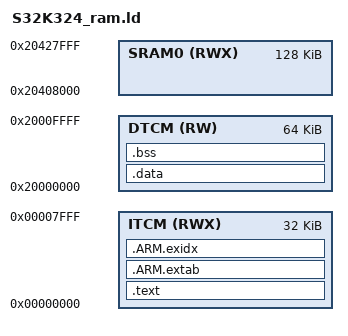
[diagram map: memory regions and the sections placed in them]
/*****************************************************************************
 *
 * Copyright 2020-2022 NXP
 * All Rights Reserved
 *
 *****************************************************************************
 *
 * THIS SOFTWARE IS PROVIDED BY NXP "AS IS" AND ANY EXPRESSED OR
 * IMPLIED WARRANTIES, INCLUDING, BUT NOT LIMITED TO, THE IMPLIED WARRANTIES
 * OF MERCHANTABILITY AND FITNESS FOR A PARTICULAR PURPOSE ARE DISCLAIMED.
 * IN NO EVENT SHALL NXP OR ITS CONTRIBUTORS BE LIABLE FOR ANY DIRECT,
 * INDIRECT, INCIDENTAL, SPECIAL, EXEMPLARY, OR CONSEQUENTIAL DAMAGES
 * (INCLUDING, BUT NOT LIMITED TO, PROCUREMENT OF SUBSTITUTE GOODS OR
 * SERVICES; LOSS OF USE, DATA, OR PROFITS; OR BUSINESS INTERRUPTION)
 * HOWEVER CAUSED AND ON ANY THEORY OF LIABILITY, WHETHER IN CONTRACT,
 * STRICT LIABILITY, OR TORT (INCLUDING NEGLIGENCE OR OTHERWISE) ARISING
 * IN ANY WAY OUT OF THE USE OF THIS SOFTWARE, EVEN IF ADVISED OF
 * THE POSSIBILITY OF SUCH DAMAGE.
 *
 ****************************************************************************/

/* Linker script to configure memory regions. */
MEMORY
{
  ITCM  (RWX) : ORIGIN = 0x00000000, LENGTH = 0x8000
  DTCM  (RW)  : ORIGIN = 0x20000000, LENGTH = 0x10000
  SRAM0 (RWX) : ORIGIN = 0x20408000, LENGTH = 0x20000
}

/* Linker script to place sections and symbol values. Should be used together
 * with other linker script that defines memory regions RAM.
 * It references following symbols, which must be defined in code:
 *   Reset_Handler : Entry of reset handler
 *
 * It defines following symbols, which code can use without definition:
 *   __exidx_start
 *   __exidx_end
 *   __ecc_table_start__
 *   __ecc_table_end__
 *   __etext
 *   __data_start__
 *   __preinit_array_start
 *   __preinit_array_end
 *   __init_array_start
 *   __init_array_end
 *   __fini_array_start
 *   __fini_array_end
 *   __data_end__
 *   __bss_start__
 *   __bss_end__
 *   __end__
 *   end
 *   __HeapLimit
 *   __StackLimit
 *   __StackTop
 *   __stack
 */
ENTRY(Reset_Handler)

SECTIONS
{
  .text :
  {
    . = ALIGN(8);
    KEEP(*(.vectors))
    *(.text*)

    KEEP(*(.init))
    KEEP(*(.fini))

    /* .ctors */
    *crtbegin.o(.ctors)
    *crtbegin?.o(.ctors)
    *(EXCLUDE_FILE(*crtend?.o *crtend.o) .ctors)
    *(SORT(.ctors.*))
    *(.ctors)

    /* .dtors */
     *crtbegin.o(.dtors)
     *crtbegin?.o(.dtors)
     *(EXCLUDE_FILE(*crtend?.o *crtend.o) .dtors)
     *(SORT(.dtors.*))
     *(.dtors)

    *(.rodata*)
    KEEP(*(.eh_frame*))
    . = ALIGN(8);
  } > ITCM

  .ARM.extab :
  {
    *(.ARM.extab* .gnu.linkonce.armextab.*)
  } > ITCM

  __exidx_start = .;
  .ARM.exidx :
  {
    *(.ARM.exidx* .gnu.linkonce.armexidx.*)
  } > ITCM
  __exidx_end = .;

  /* Due ECC initialization sequence __data_start__ and __data_end__ should be aligned on 8 bytes */
  .data :
  {
    . = ALIGN(8);
    __etext = .;
    __data_start__ = .;
    *(vtable)
    *(.data)
    *(.data.*)
    /* All data end */
    __data_end__ = .;

  } > DTCM

  /* Due ECC initialization sequence __bss_start__ and __bss_end__ should be aligned on 8 bytes */
  .bss :
  {
    . = ALIGN(8);
    __bss_start__ = .;
    *(.bss)
    *(.bss.*)
    *(COMMON)
    . = ALIGN(8);
    __bss_end__ = .;
  } > DTCM

  PROVIDE(__stack = __StackTop);

}
